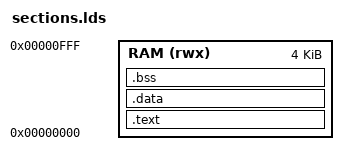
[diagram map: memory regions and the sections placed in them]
/* AUTO-GENERATED BY gen_config.py - DO NOT EDIT MANUALLY */
/* Generated: 2026-03-26 19:16:47 */

OUTPUT_ARCH(riscv)
ENTRY(_start)

MEMORY { RAM (rwx) : ORIGIN = 0x00000000, LENGTH = 4096 }

SECTIONS {
  .text  : { *(.text.start) *(.text*) *(.rodata*) } > RAM
  .data  : { *(.data*) } > RAM
  .bss   : {
    __bss_start = .;
    *(.bss*) *(COMMON)
    __bss_end = .;
  } > RAM
  _stack_top = ORIGIN(RAM) + LENGTH(RAM);
}
